# DSS0_VP1 register map
Vendor: Texas Instruments
Peripheral module from a debugger description file (folder J7ES).
Registers are 32-bit, read-write, reset 0x0 unless marked. A register's access mark holds for its fields unless they carry their own. Offsets are as the file gives them; lines under a group give offsets from that group; [hi:lo] are bit positions; {n}, {i} and the like mark numbered series; 'fields as' and 'values as' point back to an identical list; <NAME> marks a mode.

## DSS0_VP1
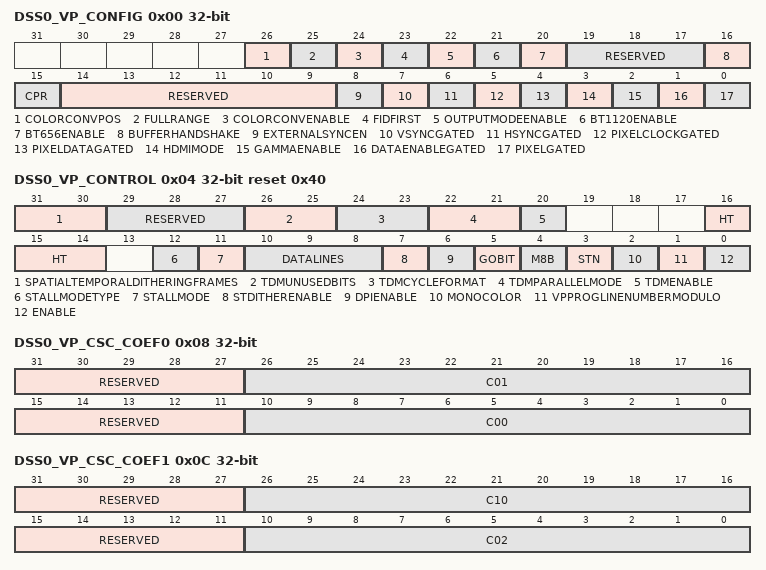
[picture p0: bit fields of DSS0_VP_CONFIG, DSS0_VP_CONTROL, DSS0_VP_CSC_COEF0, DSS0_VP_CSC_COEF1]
0x00 DSS0_VP_CONFIG access per field — The register configures the Display Controller module for the VP output. Shadow register.
  [26] COLORCONVPOS rw — Determines the position of the COLORCONV module
  [25] FULLRANGE rw — Color Space Conversion full range setting
  [24] COLORCONVENABLE rw — Enable the color space conversion.
  [23] FIDFIRST rw — Selects the first field to output in case of interlace mode.
  [22] OUTPUTMODEENABLE rw — Selects between progressive and interlace mode for the VP output
  [21] BT1120ENABLE rw — Selects BT-1120 format on the VP output.
  [20] BT656ENABLE rw — Selects BT-656 format on the VP output.
  [19:17] RESERVED ro — Write 0's for future compatibility Reads return 0
  [16] BUFFERHANDSHAKE rw — Deprecated.
  [15] CPR rw — Deprecated.
  [14:9] RESERVED ro — Write 0's for future compatibility Reads return 0
  [8] EXTERNALSYNCEN rw — Deprecated.
  [7] VSYNCGATED rw — VSYNC Gated Enabled [VP output].
  [6] HSYNCGATED rw — HSYNC Gated Enabled [VP output].
  [5] PIXELCLOCKGATED rw — Pixel Clock Gated Enabled [VP output].
  [4] PIXELDATAGATED rw — Pixel Data Gated Enabled [VP output].
  [3] HDMIMODE rw — Deprecated.
  [2] GAMMAENABLE rw — Enable the gamma Shadow bit-field
  [1] DATAENABLEGATED rw — DE Gated Enable Shadow bit-field
  [0] PIXELGATED rw — Pixel Gated Enable.
0x04 DSS0_VP_CONTROL access per field reset 0x40 — The register configures the Display Controller module for the VP output
  [31:30] SPATIALTEMPORALDITHERINGFRAMES rw — Spatial/Temporal dithering number of frames for the VP output Shadow bit-field
  [29:27] RESERVED ro — Write 0's for future compatibility Reads return 0
  [26:25] TDMUNUSEDBITS rw — State of unused bits [TDM mode only] for the VP output Shadow bit-field
  [24:23] TDMCYCLEFORMAT rw — Cycle format [TDM mode only] for the VP output Shadow bit-field
  [22:21] TDMPARALLELMODE rw — Output Interface width [TDM mode only] for the VP output Shadow bit-field
  [20] TDMENABLE rw — Enable the multiple cycle format for the VP output Shadow bit-field
  [16:14] HT rw — Hold Time for output.
  [12] STALLMODETYPE rw — The type of transfer in STALLMODE - If STALLMODE is enabled
  [11] STALLMODE rw — Enable the STALLMODE on DPI output
  [10:8] DATALINES rw — Width of the data bus on VP output Shadow bit-field
  [7] STDITHERENABLE rw — Spatial Temporal dithering enable for the VP output Shadow bit-field
  [6] DPIENABLE rw — Enable the DPI output.
  [5] GOBIT rw — GO Command for the VP output.
  [4] M8B rw — Deprecated.
  [3] STN rw — Deprecated.
  [2] MONOCOLOR rw — Deprecated.
  [1] VPPROGLINENUMBERMODULO rw — Enable the modulo of the line number interrupt generation
  [0] ENABLE rw — Enable the video port output.
0x08 DSS0_VP_CSC_COEF0 access per field — The register configures the color space conversion matrix coefficients. Shadow register
  [31:27] RESERVED ro — Write 0's for future compatibility.
  [26:16] C01 rw — C01 Coefficient.
  [15:11] RESERVED ro — Write 0's for future compatibility.
  [10:0] C00 rw — C00 Coefficient.
0x0C DSS0_VP_CSC_COEF1 access per field — The register configures the color space conversion matrix coefficients. Shadow register
  [31:27] RESERVED ro — Write 0's for future compatibility.
  [26:16] C10 rw — C10 Coefficient.
  [15:11] RESERVED ro — Write 0's for future compatibility.
  [10:0] C02 rw — C02 Coefficient.
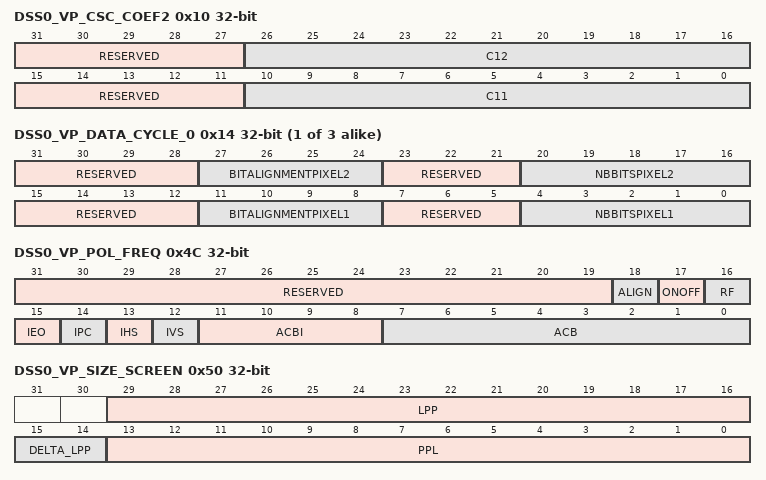
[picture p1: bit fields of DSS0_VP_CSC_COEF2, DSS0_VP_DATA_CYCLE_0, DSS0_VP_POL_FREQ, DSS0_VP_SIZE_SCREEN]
0x10 DSS0_VP_CSC_COEF2 access per field — The register configures the color space conversion matrix coefficients. Shadow register
  [31:27] RESERVED ro — Write 0's for future compatibility Reads return 0
  [26:16] C12 rw — C12 Coefficient.
  [15:11] RESERVED ro — Write 0's for future compatibility Reads return 0
  [10:0] C11 rw — C11 Coefficient.
{0x14+4i} DSS0_VP_DATA_CYCLE_{i} access per field (i=0..2) — The register configures the output data format over up to 3 cycles. Shadow register
  [31:28] RESERVED ro — Write 0's for future compatibility Reads return 0
  [27:24] BITALIGNMENTPIXEL2 rw — Bit alignment Alignment of the bits from pixel 2 on the output interface
  [23:21] RESERVED ro — Write 0's for future compatibility Reads return 0
  [20:16] NBBITSPIXEL2 rw — Number of bits Number of bits from the pixel 2 [value from 0 to 16 bits].
  [15:12] RESERVED ro — Write 0's for future compatibility.
  [11:8] BITALIGNMENTPIXEL1 rw — Bit alignment Alignment of the bits from pixel 1 on the output interface
  [7:5] RESERVED ro — Write 0's for future compatibility Reads return 0
  [4:0] NBBITSPIXEL1 rw — Number of bits Number of bits from the pixel 1 [value from 0 to 16 bits].
0x44 DSS0_VP_LINE_NUMBER access per field — The register indicates the panel display line number for the interrupt and the DMA request. Shadow register
  [13:0] LINENUMBER rw — LCD panel line number programming LCD line number defines the line on which the programmable interrupt is generated and the DMA request occurs
0x4C DSS0_VP_POL_FREQ access per field — The register configures the signal configuration. Shadow register
  [31:19] RESERVED ro — Write 0's for future compatibility Reads return 0
  [18] ALIGN rw — Defines the alignment between HSYNC and VSYNC assertion
  [17] ONOFF rw — HSYNC/VSYNC Pixel clock
  [16] RF rw — Program HSYNC/VSYNC Rise or Fall
  [15] IEO rw — Invert output enable
  [14] IPC rw — Invert pixel clock
  [13] IHS rw — Invert HSYNC
  [12] IVS rw — Invert VSYNC
  [11:8] ACBI rw — AC Bias Pin transitions per interrupt Value [from 0 to 15] used to specify the number of AC Bias pin transitions
  [7:0] ACB rw — AC Bias Pin Frequency Value [from 0 to 255] used to specify the number of line clocks to count before transitioning the AC Bias pin.
0x50 DSS0_VP_SIZE_SCREEN — The register configures the panel size horizontal and vertical. Shadow register. A delta value is used to indicate if the odd field has same vertical size as the even field or +/- one line.
  [29:16] LPP — Lines per panel Encoded value [from 1 to 16384] to specify the number of lines per panel [program to value minus one]
  [15:14] DELTA_LPP — Indicates the delta size value of the odd field compared to the even field
  [13:0] PPL — Pixels per line Encoded value [from 1 to 16384] to specify the number of pixels contains within each line on the display [program to value minus one].
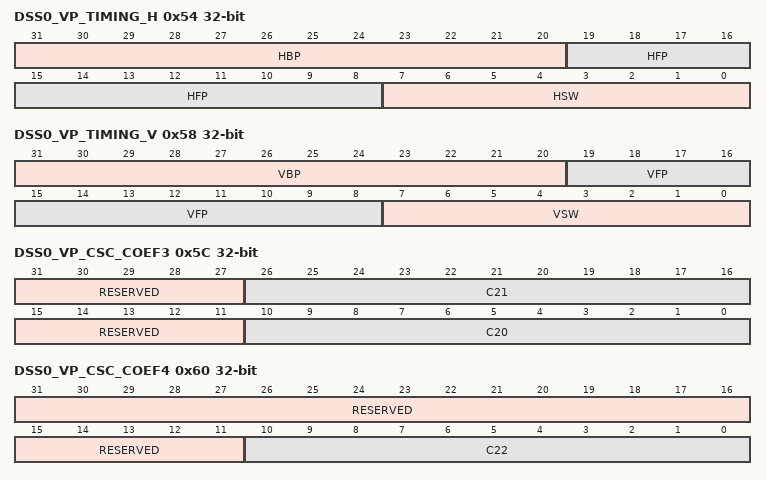
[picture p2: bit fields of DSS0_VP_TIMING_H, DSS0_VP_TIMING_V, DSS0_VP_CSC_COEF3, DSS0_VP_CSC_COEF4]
0x54 DSS0_VP_TIMING_H — The register configures the timing logic for the HSYNC signal. Shadow register
  [31:20] HBP — Horizontal Back Porch Encoded value [from 1 to 4096] to specify the number of pixel clock periods to add to the beginning of a line transmission before the first set of pixels is output to the display [program to value minus one] When in BT mode and interlaced, this field corresponds to the vertical field blanking No 2 for Even Field
  [19:8] HFP — Horizontal front porch Encoded value [from 1 to 4096] to specify the number of pixel clock periods to add to the end of a line transmission before line clock is asserted display [program to value minus one] When in BT mode and interlaced, this field corresponds to the vertical field blanking No 1 for Even Field
  [7:0] HSW — Horizontal synchronization pulse width Encoded value [from 1 to 256] to specify the number of pixel clock periods to pulse the line clock at the end of each line display [program to value minus one] When in BT mode, this field corresponds to the LSB
0x58 DSS0_VP_TIMING_V — The register configures the timing logic for the VSYNC signal. Shadow register
  [31:20] VBP — Vertical back porch Encoded value [from 0 to 4095] to specify the number of line clock periods to add to the beginning of a frame When in BT mode and interlaced, this field corresponds to the vertical field blanking No 2 for Odd Field When in BT and in progressive mode, this field corresponds to the Vertical frame blanking No 2 before the first set of pixels is output to the display
  [19:8] VFP — Vertical front porch Encoded value [from 0 to 4095] to specify the number of line clock periods to add to the end of each frame When in BT mode and interlaced, this field corresponds to the vertical field blanking No 1 for Odd Field When in BT and in progressive mode, this field corresponds to the Vertical frame blanking No 2
  [7:0] VSW — Vertical synchronization pulse width Encoded value [from 1 to 256] to specify the number of line clock periods to pulse the frame clock [VSYNC] pin at the end of each frame after the end of frame wait [VFP] period elapses Frame clock uses as VSYNC signal in active mode When in BT mode, the lsb
0x5C DSS0_VP_CSC_COEF3 access per field — The register configures the color space conversion matrix coefficients. Shadow register
  [31:27] RESERVED ro — Write 0's for future compatibility.
  [26:16] C21 rw — C21 coefficient.
  [15:11] RESERVED ro — Write 0's for future compatibility.
  [10:0] C20 rw — C20 coefficient.
0x60 DSS0_VP_CSC_COEF4 access per field — The register configures the color space conversion matrix coefficients. Shadow register
  [31:11] RESERVED ro — Write 0's for future compatibility.
  [10:0] C22 rw — C22 Coefficient.
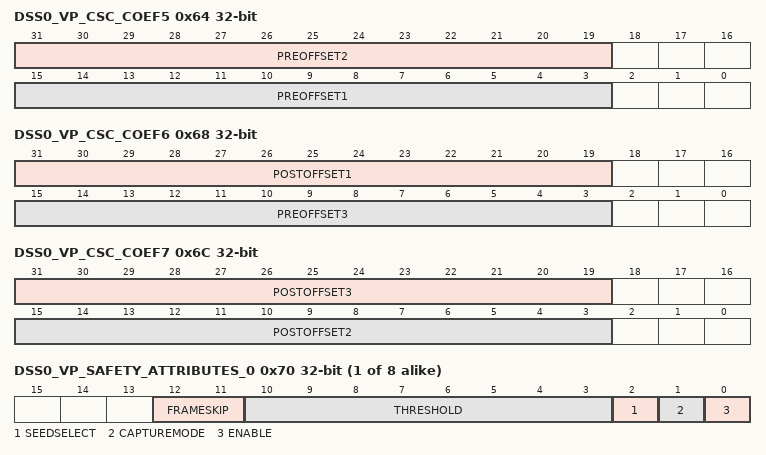
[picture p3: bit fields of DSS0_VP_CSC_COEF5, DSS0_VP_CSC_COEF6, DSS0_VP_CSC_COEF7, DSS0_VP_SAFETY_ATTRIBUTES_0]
0x64 DSS0_VP_CSC_COEF5 access per field — The register configures the color space conversion matrix coefficients. Shadow register
  [31:19] PREOFFSET2 rw — Row-2 pre-offset.
  [15:3] PREOFFSET1 rw — Row1 pre-offset.
0x68 DSS0_VP_CSC_COEF6 access per field — The register configures the color space conversion matrix coefficients. Shadow register
  [31:19] POSTOFFSET1 rw — Row-1 post-offset.
  [15:3] PREOFFSET3 rw — Row-3 pre-offset.
0x6C DSS0_VP_CSC_COEF7 access per field — The register configures the color space conversion matrix coefficients. Shadow register
  [31:19] POSTOFFSET3 rw — Row-3 post-offset.
  [15:3] POSTOFFSET2 rw — Row-2 post-offset.
{0x70+4i} DSS0_VP_SAFETY_ATTRIBUTES_{i} access per field (i=0..7) — The register configures the safety sub-region n. Shadow register
  [12:11] FRAMESKIP rw — Indicates which frames to be skipped while doing FRAMEFREEZE or DATACHECK [Useful for interlaced displays].
  [10:3] THRESHOLD rw — Allowed maximum number of frames with the same frame signature When the freeze frame counter reaches 1 over this value [freeze_frame_thold+1], a freeze frame detection will occur Note: The freeze frame counter is cleared on reset -OR- MISR not enabled -OR- terminal count reached -OR- compare == no match
  [2] SEEDSELECT rw — Initial seed selection
  [1] CAPTUREMODE rw — Mode of operation of the safety check module
  [0] ENABLE rw — Safety check Enable for the region Note: Transition from 0 to 1 clears the signature register
{0x90+4i} DSS0_VP_SAFETY_CAPT_SIGNATURE_{i} ro (i=0..7) — The register captures the signature from the MISR of the safety sub-region n. Shadow register
  [31:0] SIGNATURE — The register configures the reference signature of the safety sub-region n Shadow register
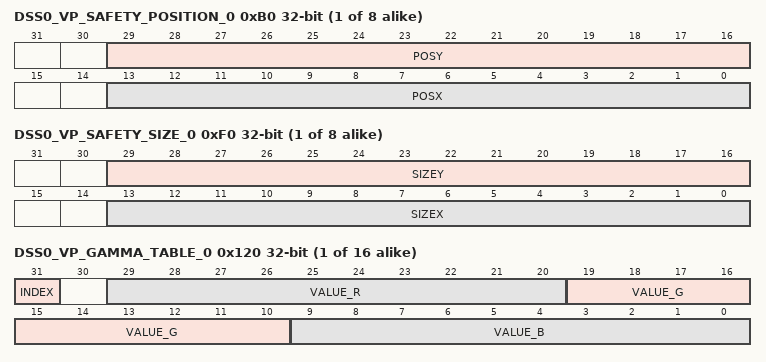
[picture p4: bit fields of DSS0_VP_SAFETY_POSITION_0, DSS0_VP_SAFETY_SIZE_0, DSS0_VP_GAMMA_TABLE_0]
{0xB0+4i} DSS0_VP_SAFETY_POSITION_{i} (i=0..7) — The register configures the position of the safety sub-region n. Shadow register
  [29:16] POSY — Y position of the safety sub-region n.
  [13:0] POSX — X position of the safety sub-region n.
{0xD0+4i} DSS0_VP_SAFETY_REF_SIGNATURE_{i} (i=0..7) — The register configures the reference signature of the safety sub-region n. Shadow register
  [31:0] SIGNATURE — The register configures the reference signature of the safety sub-region n.
{0xF0+4i} DSS0_VP_SAFETY_SIZE_{i} (i=0..7) — The register configures the size of the safety sub-region n Shadow register.
  [29:16] SIZEY — Height of the safety sub-region n Encoded value [from 0 to 16383] to specify the height of the sub-region on the screen One line height region has value of 0
  [13:0] SIZEX — Width of the safety sub-region n Encoded value [from 0 to 16383] to specify the width of the sub-region on the screen One pixel wide region has value of 0
0x110 DSS0_VP_SAFETY_LFSR_SEED — The register configures the seed initial signature value of MISRs that are to be initialized with a user programmed initial value. Otherwise, the MISR is initialized with 0xFFFF_FFFF. Shadow register.
  [31:0] SEED — The register configures the seed [initial signature value] of MISRs that are to be initialized with a user programmed initial value Otherwise, the MISR is initialized with 0xFFFF_FFFF Shadow register
{0x120+4i} DSS0_VP_GAMMA_TABLE_{i} wo (i=0..15) — The register configures the gamma table on VP output.
  [31] INDEX — Write 1 to reset the index
  [29:20] VALUE_R
  [19:10] VALUE_G
  [9:0] VALUE_B
0x178 DSS0_VP_SECURE access per field — Security bit settings for the sub-module
  [0] SECURE rw
